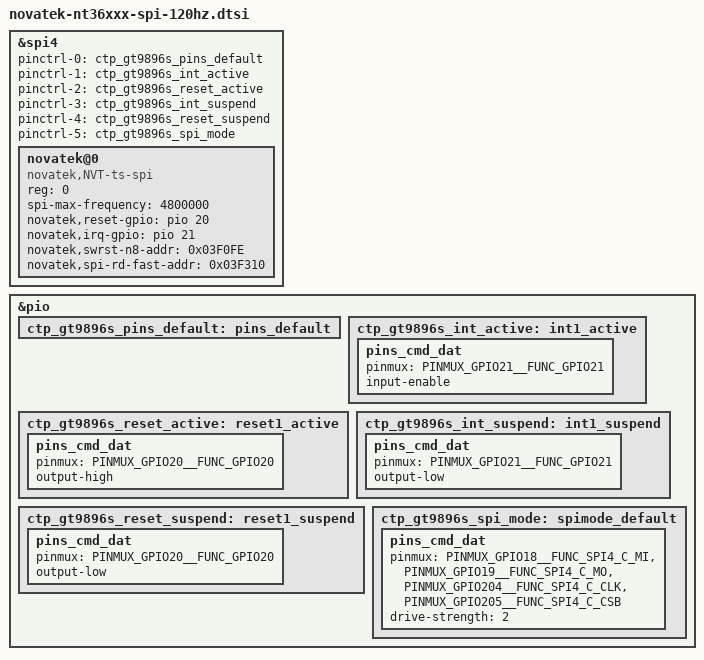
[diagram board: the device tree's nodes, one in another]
/*
 * Copyright (C) 2010 - 2018 Novatek, Inc.
 *
 * $Revision$
 * $Date$
 *
 * This program is free software; you can redistribute it and/or modify
 * it under the terms of the GNU General Public License as published by
 * the Free Software Foundation; either version 2 of the License, or
 * (at your option) any later version.
 *
 * This program is distributed in the hope that it will be useful, but WITHOUT
 * ANY WARRANTY; without even the implied warranty of MERCHANTABILITY or
 * FITNESS FOR A PARTICULAR PURPOSE.  See the GNU General Public License for
 * more details.
 *
 */
&spi4 {
	status = "okay";
	#address-cells = <1>;
	#size-cells = <0>;
	pinctrl-names = "default", "gt9896s_int_active",
		"gt9896s_reset_active", "gt9896s_int_suspend",
		"gt9896s_reset_suspend", "gt9896s_spi_mode";
	pinctrl-0 = <&ctp_gt9896s_pins_default>;
	pinctrl-1 = <&ctp_gt9896s_int_active>;
	pinctrl-2 = <&ctp_gt9896s_reset_active>;
	pinctrl-3 = <&ctp_gt9896s_int_suspend>;
	pinctrl-4 = <&ctp_gt9896s_reset_suspend>;
	pinctrl-5 = <&ctp_gt9896s_spi_mode>;

	/* Novatek device tree node */
	novatek@0 {
		compatible = "novatek,NVT-ts-spi";
		reg = <0>; //Same as CS ID
		status = "okay";
		//4800000,9600000,15000000,19200000
		spi-max-frequency = <4800000>;

		novatek,reset-gpio = <&pio 20 0x00>;
		novatek,irq-gpio = <&pio 21 0x00>;

		/* 525 */
		//novatek,swrst-n8-addr = <0x01F01A>;

		/* 672A, 525B, 675, 526 */
		novatek,swrst-n8-addr = <0x03F0FE>;
		novatek,spi-rd-fast-addr = <0x03F310>;
	};
};

&pio {
	ctp_gt9896s_pins_default: pins_default {
	};
	ctp_gt9896s_int_active: int1_active {
		pins_cmd_dat {
			pinmux = <PINMUX_GPIO21__FUNC_GPIO21>;
			input-enable;
		};
	};
	ctp_gt9896s_reset_active: reset1_active {
		pins_cmd_dat {
			pinmux = <PINMUX_GPIO20__FUNC_GPIO20>;
			output-high;
		};
	};
	ctp_gt9896s_int_suspend: int1_suspend {
		pins_cmd_dat {
			pinmux = <PINMUX_GPIO21__FUNC_GPIO21>;
			output-low;
		};
	};
	ctp_gt9896s_reset_suspend: reset1_suspend {
		pins_cmd_dat {
			pinmux = <PINMUX_GPIO20__FUNC_GPIO20>;
			output-low;
		};
	};
	ctp_gt9896s_spi_mode: spimode_default {
		pins_cmd_dat {
			pinmux = <PINMUX_GPIO18__FUNC_SPI4_C_MI>,
				<PINMUX_GPIO19__FUNC_SPI4_C_MO>,
				<PINMUX_GPIO204__FUNC_SPI4_C_CLK>,
				<PINMUX_GPIO205__FUNC_SPI4_C_CSB>;
			drive-strength = <2>;
		};
	};
};
